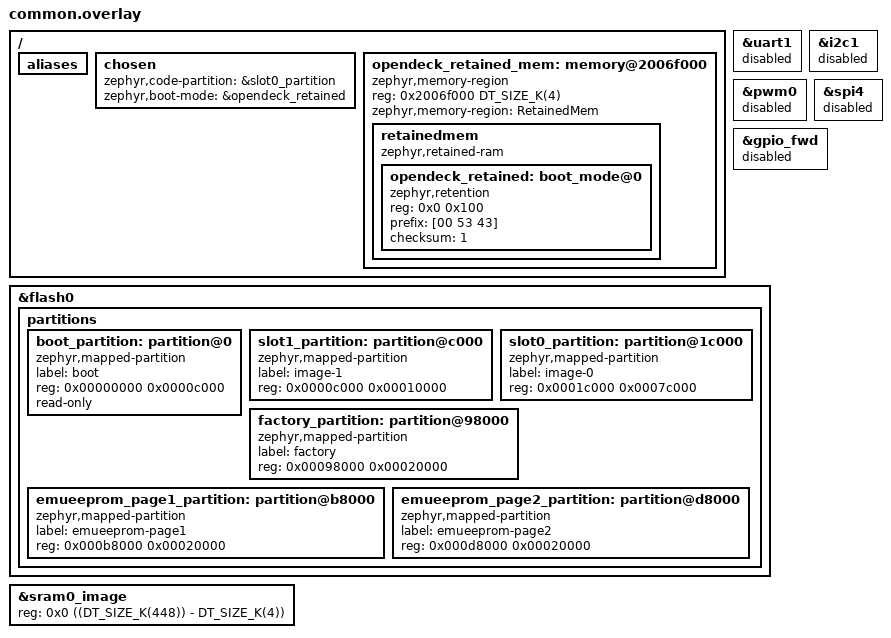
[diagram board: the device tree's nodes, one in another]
&uart1 {
    status = "disabled";
};

&i2c1 {
    status = "disabled";
};

&pwm0 {
    status = "disabled";
};

&spi4 {
    status = "disabled";
};

&gpio_fwd {
    status = "disabled";
};

/ {
    aliases {
        /delete-property/ sw0;
        /delete-property/ sw1;
        /delete-property/ sw2;
        /delete-property/ sw3;
        /delete-property/ mcuboot-button0;
        /delete-property/ led0;
        /delete-property/ led1;
        /delete-property/ led2;
        /delete-property/ led3;
        /delete-property/ pwm-led0;
        /delete-property/ mcuboot-led0;
    };

    /delete-node/ buttons;
    /delete-node/ leds;
    /delete-node/ pwmleds;
};

&flash0 {
    partitions {
        ranges;
        /delete-node/ boot_partition;
        /delete-node/ slot0_partition;
        /delete-node/ slot1_partition;
        /delete-node/ storage_partition;
        /delete-node/ partition@0;
        /delete-node/ partition@10000;
        /delete-node/ partition@84000;
        /delete-node/ partition@f8000;

        boot_partition: partition@0 {
            compatible = "zephyr,mapped-partition";
            label = "boot";
            reg = <0x00000000 0x0000c000>;
            read-only;
        };

        /* image-1 is the OpenDeck bootloader; keep it before image-0 so merged images stay compact. */
        slot1_partition: partition@c000 {
            compatible = "zephyr,mapped-partition";
            label = "image-1";
            reg = <0x0000c000 0x00010000>;
        };

        slot0_partition: partition@1c000 {
            compatible = "zephyr,mapped-partition";
            label = "image-0";
            reg = <0x0001c000 0x0007c000>;
        };

        factory_partition: partition@98000 {
            compatible = "zephyr,mapped-partition";
            label = "factory";
            reg = <0x00098000 0x00020000>;
        };

        emueeprom_page1_partition: partition@b8000 {
            compatible = "zephyr,mapped-partition";
            label = "emueeprom-page1";
            reg = <0x000b8000 0x00020000>;
        };

        emueeprom_page2_partition: partition@d8000 {
            compatible = "zephyr,mapped-partition";
            label = "emueeprom-page2";
            reg = <0x000d8000 0x00020000>;
        };
    };
};

&sram0_image {
    reg = <0x0 ((DT_SIZE_K(448)) - DT_SIZE_K(4))>;
    ranges = <0x0 0x0 ((DT_SIZE_K(448)) - DT_SIZE_K(4))>;
};

/ {
    chosen {
        zephyr,code-partition = &slot0_partition;
        zephyr,boot-mode = &opendeck_retained;
    };

    opendeck_retained_mem: memory@2006f000 {
        compatible = "zephyr,memory-region", "mmio-sram";
        reg = <0x2006f000 DT_SIZE_K(4)>;
        zephyr,memory-region = "RetainedMem";
        status = "okay";

        retainedmem {
            compatible = "zephyr,retained-ram";
            status = "okay";
            #address-cells = <1>;
            #size-cells = <1>;

            opendeck_retained: boot_mode@0 {
                compatible = "zephyr,retention";
                status = "okay";
                reg = <0x0 0x100>;
                prefix = [00 53 43];
                checksum = <1>;
            };
        };
    };
};
